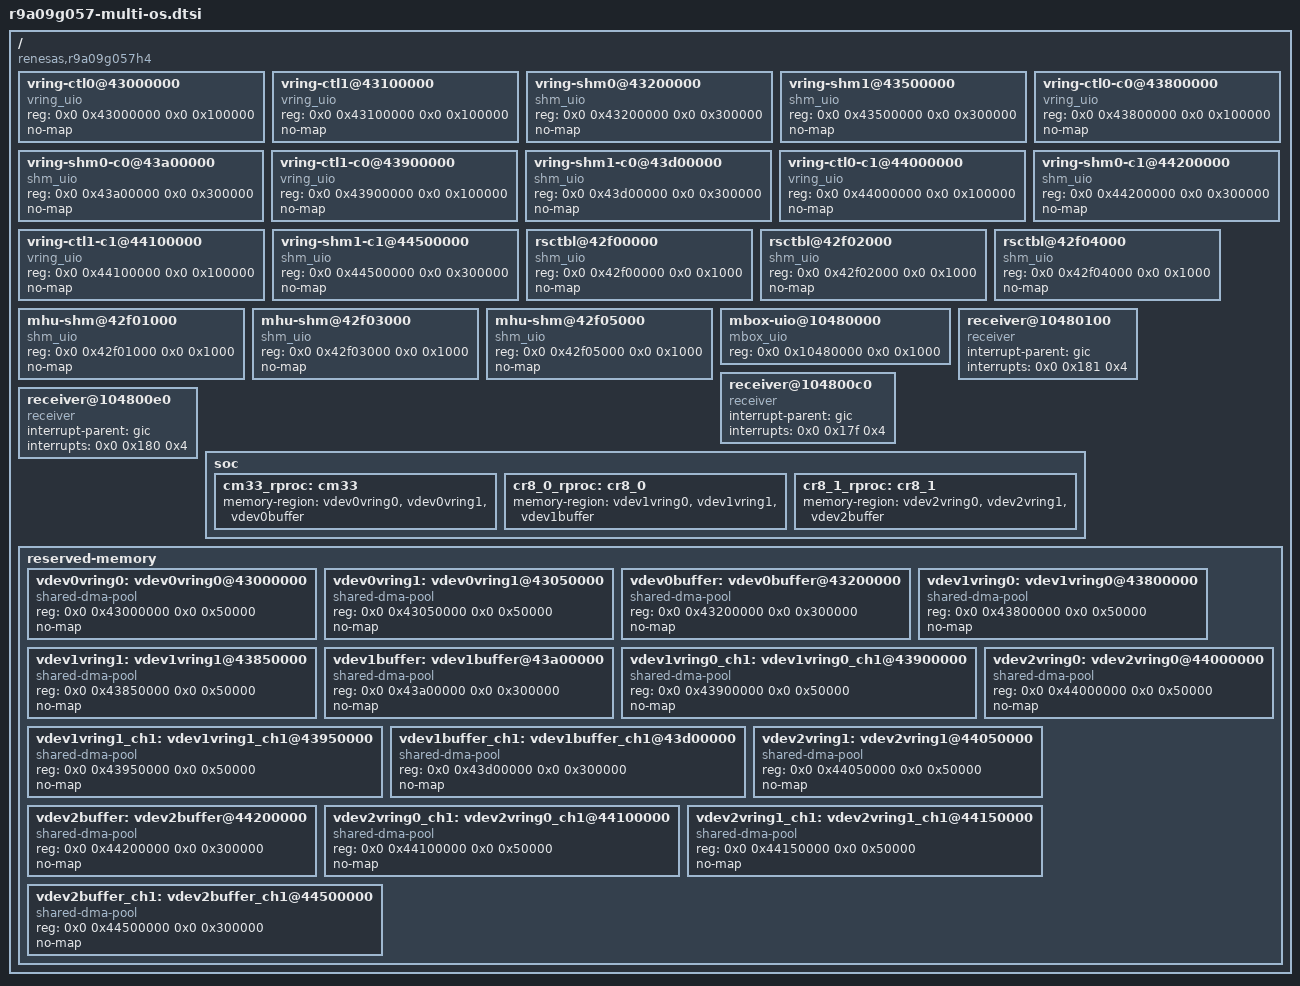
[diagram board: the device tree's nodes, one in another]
// SPDX-License-Identifier: (GPL-2.0-only OR BSD-2-Clause)
/*
 * Device Tree Source for OpenAMP-related support on the RZ/V2H SoC.
 *
 * Copyright (C) 2026 Renesas Electronics Corp.
 */

/ {
	compatible = "renesas,r9a09g057h4", "renesas,r9a09g057";

	/* ---------------------------------------------------------------- */
	/* UIO vring/shm nodes                                              */
	/* ---------------------------------------------------------------- */

	/* CM33 + CR8 core0 share these (channel 0 + channel 1) */
	vring-ctl0@43000000 {
		compatible = "vring_uio";
		reg = <0x0 0x43000000 0x0 0x100000>;
		no-map;
	};

	vring-ctl1@43100000 {
		compatible = "vring_uio";
		reg = <0x0 0x43100000 0x0 0x100000>;
		no-map;
	};

	vring-shm0@43200000 {
		compatible = "shm_uio";
		reg = <0x0 0x43200000 0x0 0x300000>;
		no-map;
	};

	vring-shm1@43500000 {
		compatible = "shm_uio";
		reg = <0x0 0x43500000 0x0 0x300000>;
		no-map;
	};

	/* CR8_0 vrings - ch0 */
	vring-ctl0-c0@43800000 {
		compatible = "vring_uio";
		reg = <0x0 0x43800000 0x0 0x100000>;
		no-map;
	};

	vring-shm0-c0@43a00000 {
		compatible = "shm_uio";
		reg = <0x0 0x43a00000 0x0 0x300000>;
		no-map;
	};

	/* CR8_0 vrings - ch1 */
	vring-ctl1-c0@43900000 {
		compatible = "vring_uio";
		reg = <0x0 0x43900000 0x0 0x100000>;
		no-map;
	};

	vring-shm1-c0@43d00000 {
		compatible = "shm_uio";
		reg = <0x0 0x43d00000 0x0 0x300000>;
		no-map;
	};

	/* CR8_1 vrings - ch0 */
	vring-ctl0-c1@44000000 {
		compatible = "vring_uio";
		reg = <0x0 0x44000000 0x0 0x100000>;
		no-map;
	};

	vring-shm0-c1@44200000 {
		compatible = "shm_uio";
		reg = <0x0 0x44200000 0x0 0x300000>;
		no-map;
	};

	/* CR8_1 vrings - ch1 */
	vring-ctl1-c1@44100000 {
		compatible = "vring_uio";
		reg = <0x0 0x44100000 0x0 0x100000>;
		no-map;
	};

	vring-shm1-c1@44500000 {
		compatible = "shm_uio";
		reg = <0x0 0x44500000 0x0 0x300000>;
		no-map;
	};

	/* ---------------------------------------------------------------- */
	/* Resource tables (per remote)                                     */
	/* ---------------------------------------------------------------- */

	rsctbl@42f00000 {
		compatible = "shm_uio";
		reg = <0x0 0x42f00000 0x0 0x1000>;
		no-map;
	};

	rsctbl@42f02000 {
		compatible = "shm_uio";
		reg = <0x0 0x42f02000 0x0 0x1000>;
		no-map;
	};

	rsctbl@42f04000 {
		compatible = "shm_uio";
		reg = <0x0 0x42f04000 0x0 0x1000>;
		no-map;
	};

	/* ---------------------------------------------------------------- */
	/* MHU shared-memory / mailbox / receivers                          */
	/* ---------------------------------------------------------------- */

	mhu-shm@42f01000 {
		compatible = "shm_uio";
		reg = <0x0 0x42f01000 0x0 0x1000>;
		no-map;
	};

	mhu-shm@42f03000 {
		compatible = "shm_uio";
		reg = <0x0 0x42f03000 0x0 0x1000>;
		no-map;
	};

	mhu-shm@42f05000 {
		compatible = "shm_uio";
		reg = <0x0 0x42f05000 0x0 0x1000>;
		no-map;
	};

	mbox-uio@10480000 {
		compatible = "mbox_uio";
		reg = <0x0 0x10480000 0x0 0x1000>;
		status = "okay";
	};

	receiver@10480100 {
		compatible = "receiver";
		interrupt-parent = <&gic>;
		interrupts = <0x0 0x181 0x4>;
		status = "okay";
	};

	receiver@104800c0 {
		compatible = "receiver";
		interrupt-parent = <&gic>;
		interrupts = <0x0 0x17f 0x4>;
		status = "okay";
	};

	receiver@104800e0 {
		compatible = "receiver";
		interrupt-parent = <&gic>;
		interrupts = <0x0 0x180 0x4>;
		status = "okay";
	};

	/* ---------------------------------------------------------------- */
	/* Remote processors                                                */
	/* ---------------------------------------------------------------- */

	soc: soc {
		cm33_rproc: cm33 {
			memory-region = <&vdev0vring0>, <&vdev0vring1>, <&vdev0buffer>;
			status = "okay";
		};

		cr8_0_rproc: cr8_0 {
			memory-region = <&vdev1vring0>, <&vdev1vring1>, <&vdev1buffer>;
			status = "okay";
		};

		cr8_1_rproc: cr8_1 {
			memory-region = <&vdev2vring0>, <&vdev2vring1>, <&vdev2buffer>;
			status = "okay";
		};
	};

	/* ---------------------------------------------------------------- */
	/* Reserved memory carveouts                                        */
	/* ---------------------------------------------------------------- */
	reserved-memory {
		#address-cells = <2>;
		#size-cells = <2>;
		ranges;

		/* CM33 ch0 */
		vdev0vring0: vdev0vring0@43000000 {
			compatible = "shared-dma-pool";
			reg = <0x0 0x43000000 0x0 0x50000>;
			no-map;
		};

		vdev0vring1: vdev0vring1@43050000 {
			compatible = "shared-dma-pool";
			reg = <0x0 0x43050000 0x0 0x50000>;
			no-map;
		};

		vdev0buffer: vdev0buffer@43200000 {
			compatible = "shared-dma-pool";
			reg = <0x0 0x43200000 0x0 0x300000>;
			no-map;
		};

		/* CR8 core0 ch0 */
		vdev1vring0: vdev1vring0@43800000 {
			compatible = "shared-dma-pool";
			reg = <0x0 0x43800000 0x0 0x50000>;
			no-map;
		};

		vdev1vring1: vdev1vring1@43850000 {
			compatible = "shared-dma-pool";
			reg = <0x0 0x43850000 0x0 0x50000>;
			no-map;
		};

		vdev1buffer: vdev1buffer@43a00000 {
			compatible = "shared-dma-pool";
			reg = <0x0 0x43a00000 0x0 0x300000>;
			no-map;
		};

		/* CR8 core0 ch1 */
		vdev1vring0_ch1: vdev1vring0_ch1@43900000 {
			compatible = "shared-dma-pool";
			reg = <0x0 0x43900000 0x0 0x50000>;
			no-map;
		};

		vdev1vring1_ch1: vdev1vring1_ch1@43950000 {
			compatible = "shared-dma-pool";
			reg = <0x0 0x43950000 0x0 0x50000>;
			no-map;
		};

		vdev1buffer_ch1: vdev1buffer_ch1@43d00000 {
			compatible = "shared-dma-pool";
			reg = <0x0 0x43d00000 0x0 0x300000>;
			no-map;
		};

		/* CR8 core1 ch0 */
		vdev2vring0: vdev2vring0@44000000 {
			compatible = "shared-dma-pool";
			reg = <0x0 0x44000000 0x0 0x50000>;
			no-map;
		};

		vdev2vring1: vdev2vring1@44050000 {
			compatible = "shared-dma-pool";
			reg = <0x0 0x44050000 0x0 0x50000>;
			no-map;
		};

		vdev2buffer: vdev2buffer@44200000 {
			compatible = "shared-dma-pool";
			reg = <0x0 0x44200000 0x0 0x300000>;
			no-map;
		};

		/* CR8 core1 ch1 */
		vdev2vring0_ch1: vdev2vring0_ch1@44100000 {
			compatible = "shared-dma-pool";
			reg = <0x0 0x44100000 0x0 0x50000>;
			no-map;
		};

		vdev2vring1_ch1: vdev2vring1_ch1@44150000 {
			compatible = "shared-dma-pool";
			reg = <0x0 0x44150000 0x0 0x50000>;
			no-map;
		};

		vdev2buffer_ch1: vdev2buffer_ch1@44500000 {
			compatible = "shared-dma-pool";
			reg = <0x0 0x44500000 0x0 0x300000>;
			no-map;
		};
	};
};
